# LPC844 register map
Vendor: nxp.com; File version: 1.0
CPU: CM0PLUS r0p0, little endian, no MPU, no FPU, VTOR, 2 interrupt priority bits
Registers are 32-bit, read-write, reset 0x0 unless marked. A register's access mark holds for its fields unless they carry their own. Offsets are from the block's base; [hi:lo] are bit positions; {n}, {i} and the like mark numbered series; 'fields as' and 'values as' point back to an identical list.

## ACOMP — LPC84x analog comparator
Base 0x40024000
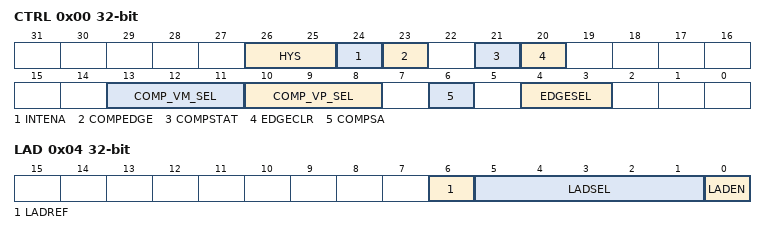
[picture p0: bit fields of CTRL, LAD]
0x00 CTRL (reset mask 0x6C03F58) — Comparator control register
  [26:25] HYS — Controls the hysteresis of the comparator. When the comparator is outputting a certain state, this is the difference between the selected signals, in the opposite direction from the state being output, that will switch the output.
    0=None (the output will switch as the voltages cross); 1=5 mv; 2=10 mv; 3=20 mv
  [24] INTENA — Must be set to generate interrupts.
  [23] COMPEDGE — Comparator edge-detect status.
  [21] COMPSTAT — Comparator status. This bit reflects the state of the comparator output.
  [20] EDGECLR — Interrupt clear bit. To clear the COMPEDGE bit and thus negate the interrupt request, toggle the EDGECLR bit by first writing a 1 and then a 0.
  [13:11] COMP_VM_SEL — Selects negative voltage input
    0=VOLTAGE_LADDER_OUTPUT; {v}=ACMP_I{v} (v=1..5); 6=BAND_GAP (Band gap. Internal reference voltage.); 7=DACOUT0 (DAC0 output)
  [10:8] COMP_VP_SEL — Selects positive voltage input
    values as COMP_VM_SEL
  [6] COMPSA — Comparator output control
    0=Comparator output is used directly; 1=Comparator output is synchronized to the bus clock for output to other modules
  [4:3] EDGESEL — This field controls which edges on the comparator output set the COMPEDGE bit (bit 23 below):
    0=FALLING_EDGES; 1=RISING_EDGES; 2=BOTH_EDGES0; 3=BOTH_EDGES1
0x04 LAD — Voltage ladder register
  [6] LADREF — Selects the reference voltage Vref for the voltage ladder.
    0=Supply pin VDD; 1=VDDCMP pin
  [5:1] LADSEL — Voltage ladder value. The reference voltage Vref depends on the LADREF bit below. 00000 = VSS 00001 = 1 x Vref/31 00010 = 2 x Vref/31 ... 11111 = Vref
  [0] LADEN — Voltage ladder enable

## INPUTMUX — LPC84x Input multiplexing (INPUT MUX)
Base 0x4002C000
{0x0+4i} DMA_INMUX_INMUX[{i}] (i=0..1) reset 0x1F — DMA output trigger selection to become DMA trigger
  [4:0] INP — DMA trigger output number (decimal value) for DMA channel n (n = 0 to 24).
{0x20+4i} SCT_INMUX[{i}] (i=0..3) reset 0x1F — input select register for SCT
  [3:0] INP_N — Input mux register for SCT input n (n = 0 to 3). 0 = sct input 0 1=sct input 1 2= sct input 2 3= sct gpio input 3 4= adc_thcmp_irq 5 = comparator out 6 = timer ct32b0 match2 7=gpio_int_bmatch 8=arm_txev 9=arm_halted
{0x40+4i} DMA_ITRIG_INMUX[{i}] (i=0..24) reset 0x1F — Trigger select register for DMA channel
  [3:0] INP — Trigger input number (decimal value) for DMA channel n (n = 0 to 24). 0 = ADC0 Sequence A interrupt 1 = ADC0 Sequence B interrupt 2 = SCT0 DMA request 0 3 = SCT0 DMA request 1 4= Comparator out 5 = Pin interrupt 4 6 = Pin interrupt 5 7 = Pin interrupt 6 8 = Pin interrupt 7 9= Timer CTIMER0 Match 0 dma request 10 = Timer CTIMER0 Match 1 dma request 11 = DMA output trigger mux 0 12 = DMA output trigger mux 1

## FLASH_CTRL — LPC84x NVMC flash controller
Base 0x40040000
0x10 FLASHCFG reset 0x2 — Flash configuration register
  [1:0] FLASHTIM — Flash memory access time. FLASHTIM +1 is equal to the number of system clocks used for flash access.
    0=ONE_SYSTEM_CLOCK_FLASH_ACCESS (1 system clock flash access time.); 1=TWO_SYSTEM_CLOCK_FLASH_ACCESS (2 system clock flash access time.); 2=THREE_SYSTEM_CLOCK_FLASH_ACCESS (3 system clock flash access time.)
0x20 FMSSTART — Flash signature start address register
  [16:0] START — Signature generation start address (corresponds to AHB byte address bits[18:2]).
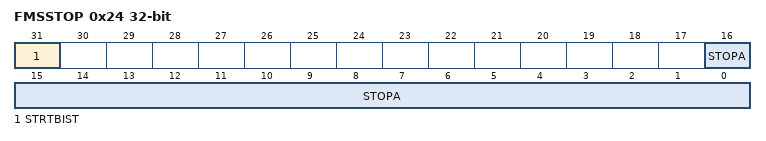
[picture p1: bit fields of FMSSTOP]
0x24 FMSSTOP — Flash signaure stop address register
  [31] STRTBIST — When this bit is written to 1, signature generation starts. At the end of signature generation, this bit is automatically cleared.
  [16:0] STOPA — Stop address for signature generation (the word specified by STOP is included in the address range). The address is in units of memory words, not bytes.
0x2C FMSW0 ro reset not defined — Flash signature generation result register returns the flash signature produced by the embedded signature generator..
  [31:0] SIG — 32-bit signature.
0xFE0 FMSTAT ro — Flash signature generation status bit
  [1] SIG_DONE — This status bit is set at the end of signature computation
0xFE8 FMSTATCLR wo — Clear FLASH signature generation status bit
  [1] SIG_DONE_CLR — When the bit is written to 1, the SIGNATURE_DONE bit is cleared.
